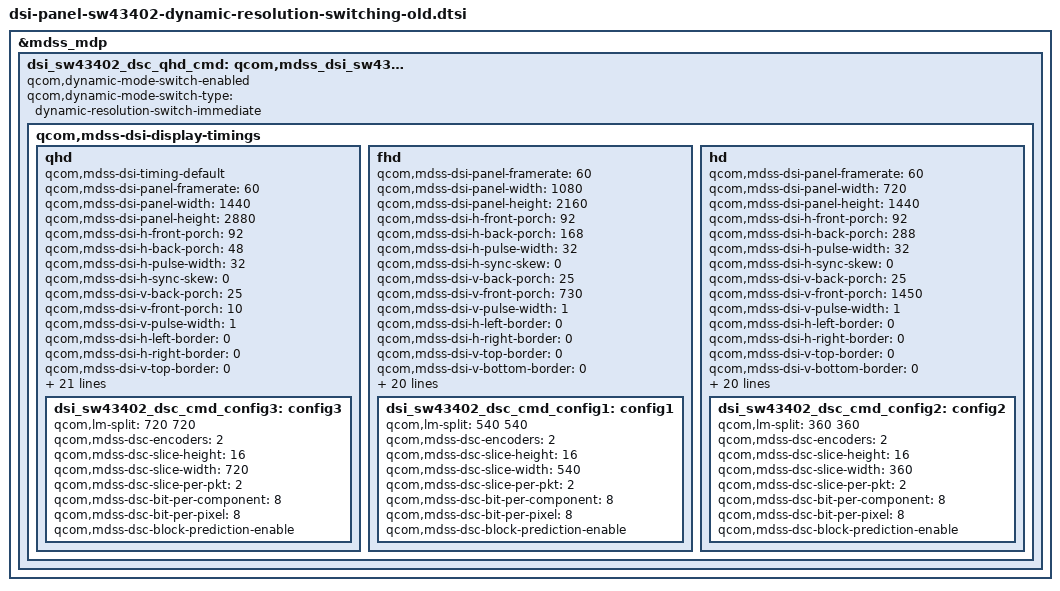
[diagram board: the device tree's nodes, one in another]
/* Copyright (c) 2014, Code Aurora Forum. All rights reserved.
 *
 * This program is free software; you can redistribute it and/or modify
 * it under the terms of the GNU General Public License version 2 and
 * only version 2 as published by the Free Software Foundation.
 *
 * This program is distributed in the hope that it will be useful,
 * but WITHOUT ANY WARRANTY; without even the implied warranty of
 * MERCHANTABILITY or FITNESS FOR A PARTICULAR PURPOSE.  See the
 * GNU General Public License for more details.
 */

&mdss_mdp {
	dsi_sw43402_dsc_qhd_cmd: qcom,mdss_dsi_sw43402_dsc_qhd_cmd {
			qcom,dynamic-mode-switch-enabled;
			qcom,dynamic-mode-switch-type = "dynamic-resolution-switch-immediate";

			qcom,mdss-dsi-display-timings {
				qhd {
					qcom,mdss-dsi-timing-default;
					qcom,mdss-dsi-panel-framerate = <60>;
					qcom,mdss-dsi-panel-width = <1440>;
					qcom,mdss-dsi-panel-height = <2880>;
					qcom,mdss-dsi-h-front-porch = <92>;
					qcom,mdss-dsi-h-back-porch = <48>;
					qcom,mdss-dsi-h-pulse-width = <32>;
					qcom,mdss-dsi-h-sync-skew = <0>;
					qcom,mdss-dsi-v-back-porch = <25>;
					qcom,mdss-dsi-v-front-porch = <10>;
					qcom,mdss-dsi-v-pulse-width = <1>;
					qcom,mdss-dsi-h-left-border = <0>;
					qcom,mdss-dsi-h-right-border = <0>;
					qcom,mdss-dsi-v-top-border = <0>;
					qcom,mdss-dsi-v-bottom-border = <0>;
					qcom,mdss-dsi-panel-timings = [00 14 05 05 08 0E 04 05 04 03 04 00];
					qcom,mdss-dsi-t-clk-post = <0x06>;
					qcom,mdss-dsi-t-clk-pre = <0x20>;
					qcom,panel-roi-alignment = <1440 0 1440 16 1440 16>;

					qcom,mdss-dsi-on-command = [
						39 01 00 00 00 00 03 B0 20 43
						15 01 00 00 00 00 02 3D 00
						39 01 00 00 00 00 03 DF 4B 70
						15 01 00 00 00 00 02 F2 00
						39 01 00 00 01 00 03 FF 03 00
						05 01 00 00 14 00 01 35
						05 01 00 00 14 00 01 11
						15 01 00 00 00 00 02 51 03
						15 01 00 00 00 00 02 53 07
						15 01 00 00 00 00 02 55 0C
						39 01 00 00 00 00 03 B0 A5 00
						39 01 00 00 00 00 05 E8 08 90 10 25
						39 01 00 00 00 00 03 FB 03 77
						39 01 00 00 14 00 06 ED 13 00 07 00 13
						39 01 00 00 46 00 0F E2 20 0D 08 A8 0A AA 04 A4 80 80 80 5C 5C 5C
						];
					qcom,mdss-dsi-on-command-state = "dsi_lp_mode";

					qcom,mdss-dsi-post-panel-on-command = [
						39 01 00 00 3C 00 03 B0 A5 00
						05 01 00 00 00 00 01 29
						];

					qcom,mdss-dsi-timing-switch-command = [
						15 01 00 00 00 00 02 3D 00
						];
					qcom,mdss-dsi-timing-switch-command-state = "dsi_lp_mode";

					qcom,compression-mode = "dsc";
					qcom,config-select = <&dsi_sw43402_dsc_cmd_config3>;
					qcom,mdss-dsc-version = <0x11>;
					qcom,mdss-dsc-scr-version = <0x1>;

					dsi_sw43402_dsc_cmd_config3: config3 {
						qcom,lm-split = <720 720>;
						qcom,mdss-dsc-encoders = <2>;
						qcom,mdss-dsc-slice-height = <16>;
						qcom,mdss-dsc-slice-width = <720>;
						qcom,mdss-dsc-slice-per-pkt = <2>;

						qcom,mdss-dsc-bit-per-component = <8>;
						qcom,mdss-dsc-bit-per-pixel = <8>;
						qcom,mdss-dsc-block-prediction-enable;
					};
				};
				fhd {
					qcom,mdss-dsi-panel-framerate = <60>;
					qcom,mdss-dsi-panel-width = <1080>;
					qcom,mdss-dsi-panel-height = <2160>;
					qcom,mdss-dsi-h-front-porch = <92>;
					qcom,mdss-dsi-h-back-porch = <168>;
					qcom,mdss-dsi-h-pulse-width = <32>;
					qcom,mdss-dsi-h-sync-skew = <0>;
					qcom,mdss-dsi-v-back-porch = <25>;
					qcom,mdss-dsi-v-front-porch = <730>;
					qcom,mdss-dsi-v-pulse-width = <1>;
					qcom,mdss-dsi-h-left-border = <0>;
					qcom,mdss-dsi-h-right-border = <0>;
					qcom,mdss-dsi-v-top-border = <0>;
					qcom,mdss-dsi-v-bottom-border = <0>;
					qcom,mdss-dsi-panel-timings = [00 14 05 05 08 0E 04 05 04 03 04 00];
					qcom,mdss-dsi-t-clk-post = <0x06>;
					qcom,mdss-dsi-t-clk-pre = <0x20>;
					qcom,panel-roi-alignment = <1440 0 1440 16 1440 16>;

					qcom,mdss-dsi-on-command = [
						39 01 00 00 00 00 03 B0 20 43
						15 01 00 00 00 00 02 3D 01
						39 01 00 00 00 00 03 DF 4B 70
						15 01 00 00 00 00 02 F2 00
						39 01 00 00 01 00 03 FF 03 00
						05 01 00 00 14 00 01 35
						05 01 00 00 14 00 01 11
						15 01 00 00 00 00 02 51 03
						15 01 00 00 00 00 02 53 07
						15 01 00 00 00 00 02 55 0C
						39 01 00 00 00 00 03 B0 A5 00
						39 01 00 00 00 00 05 E8 08 90 10 25
						39 01 00 00 00 00 03 FB 03 77
						39 01 00 00 14 00 06 ED 13 00 07 00 13
						39 01 00 00 46 00 0F E2 20 0D 08 A8 0A AA 04 A4 80 80 80 5C 5C 5C
						];
					qcom,mdss-dsi-on-command-state = "dsi_lp_mode";

					qcom,mdss-dsi-post-panel-on-command = [
						39 01 00 00 3C 00 03 B0 A5 00
						05 01 00 00 00 00 01 29
						];

					qcom,mdss-dsi-timing-switch-command = [
						15 01 00 00 00 00 02 3D 01
						];
					qcom,mdss-dsi-timing-switch-command-state = "dsi_lp_mode";

					qcom,compression-mode = "dsc";
					qcom,config-select = <&dsi_sw43402_dsc_cmd_config1>;
					qcom,mdss-dsc-version = <0x11>;
					qcom,mdss-dsc-scr-version = <0x1>;

					dsi_sw43402_dsc_cmd_config1: config1 {
						qcom,lm-split = <540 540>;

						qcom,mdss-dsc-encoders = <2>;
						qcom,mdss-dsc-slice-height = <16>;
						qcom,mdss-dsc-slice-width = <540>;
						qcom,mdss-dsc-slice-per-pkt = <2>;

						qcom,mdss-dsc-bit-per-component = <8>;
						qcom,mdss-dsc-bit-per-pixel = <8>;
						qcom,mdss-dsc-block-prediction-enable;
					};
				};
				hd {
					qcom,mdss-dsi-panel-framerate = <60>;
					qcom,mdss-dsi-panel-width = <720>;
					qcom,mdss-dsi-panel-height = <1440>;
					qcom,mdss-dsi-h-front-porch = <92>;
					qcom,mdss-dsi-h-back-porch = <288>;
					qcom,mdss-dsi-h-pulse-width = <32>;
					qcom,mdss-dsi-h-sync-skew = <0>;
					qcom,mdss-dsi-v-back-porch = <25>;
					qcom,mdss-dsi-v-front-porch = <1450>;
					qcom,mdss-dsi-v-pulse-width = <1>;
					qcom,mdss-dsi-h-left-border = <0>;
					qcom,mdss-dsi-h-right-border = <0>;
					qcom,mdss-dsi-v-top-border = <0>;
					qcom,mdss-dsi-v-bottom-border = <0>;
					qcom,mdss-dsi-panel-timings = [00 14 05 05 08 0E 04 05 04 03 04 00];
					qcom,mdss-dsi-t-clk-post = <0x06>;
					qcom,mdss-dsi-t-clk-pre = <0x20>;
					qcom,panel-roi-alignment = <1440 0 1440 16 1440 16>;

					qcom,mdss-dsi-on-command = [
						39 01 00 00 00 00 03 B0 20 43
						15 01 00 00 00 00 02 3D 03
						39 01 00 00 00 00 03 DF 4B 70
						15 01 00 00 00 00 02 F2 00
						39 01 00 00 01 00 03 FF 03 00
						05 01 00 00 14 00 01 35
						05 01 00 00 14 00 01 11
						15 01 00 00 00 00 02 51 03
						15 01 00 00 00 00 02 53 07
						15 01 00 00 00 00 02 55 0C
						39 01 00 00 00 00 03 B0 A5 00
						39 01 00 00 00 00 05 E8 08 90 10 25
						39 01 00 00 00 00 03 FB 03 77
						39 01 00 00 14 00 06 ED 13 00 07 00 13
						39 01 00 00 46 00 0F E2 20 0D 08 A8 0A AA 04 A4 80 80 80 5C 5C 5C
						];

					qcom,mdss-dsi-on-command-state = "dsi_lp_mode";

					qcom,mdss-dsi-post-panel-on-command = [
						39 01 00 00 3C 00 03 B0 A5 00
						05 01 00 00 00 00 01 29
						];

					qcom,mdss-dsi-timing-switch-command = [
						15 01 00 00 00 00 02 3D 03
						];
					qcom,mdss-dsi-timing-switch-command-state = "dsi_lp_mode";

					qcom,compression-mode = "dsc";
					qcom,config-select = <&dsi_sw43402_dsc_cmd_config2>;
					qcom,mdss-dsc-version = <0x11>;
					qcom,mdss-dsc-scr-version = <0x1>;

					dsi_sw43402_dsc_cmd_config2: config2 {
						qcom,lm-split = <360 360>;
						qcom,mdss-dsc-encoders = <2>;
						qcom,mdss-dsc-slice-height = <16>;
						qcom,mdss-dsc-slice-width = <360>;
						qcom,mdss-dsc-slice-per-pkt = <2>;

						qcom,mdss-dsc-bit-per-component = <8>;
						qcom,mdss-dsc-bit-per-pixel = <8>;
						qcom,mdss-dsc-block-prediction-enable;
					};
				};
			};
	};
};
